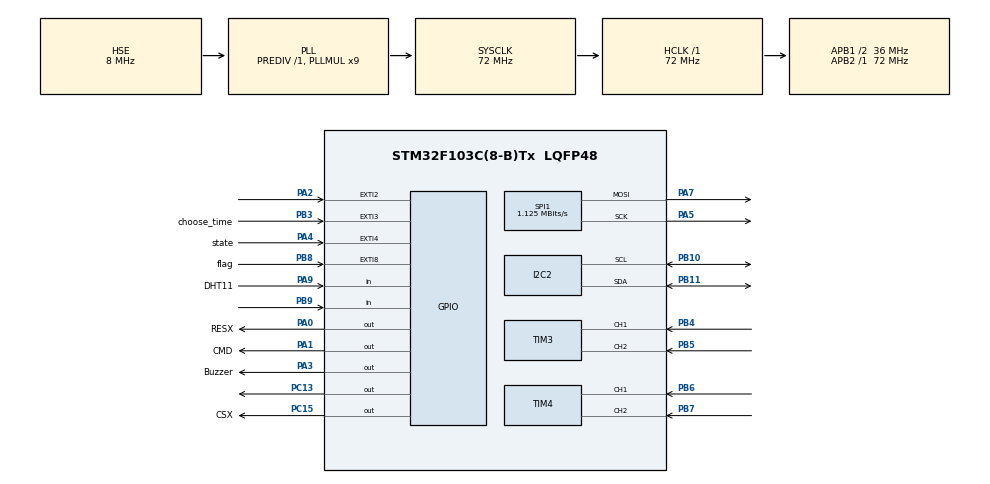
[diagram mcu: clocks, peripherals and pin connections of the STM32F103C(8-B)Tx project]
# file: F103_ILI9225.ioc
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Mcu.Family=STM32F1
Mcu.Name=STM32F103C(8-B)Tx
Mcu.Package=LQFP48
NVIC.EXTI2_IRQn=true\:0\:0\:true\:false\:true\:true\:true\:true
NVIC.EXTI3_IRQn=true\:0\:0\:true\:false\:true\:true\:true\:true
NVIC.EXTI4_IRQn=true\:0\:0\:true\:false\:true\:true\:true\:true
NVIC.EXTI9_5_IRQn=true\:0\:0\:true\:false\:true\:true\:true\:true
NVIC.PriorityGroup=NVIC_PRIORITYGROUP_4
NVIC.TIM3_IRQn=true\:1\:0\:true\:false\:true\:true\:true\:true
NVIC.TIM4_IRQn=true\:0\:0\:false\:false\:true\:true\:true\:true
PA0-WKUP.GPIO_Label=RESX
PA0-WKUP.Signal=GPIO_Output
PA1.GPIO_Label=CMD
PA1.Signal=GPIO_Output
PA13.Mode=Serial_Wire
PA13.Signal=SYS_JTMS-SWDIO
PA14.Mode=Serial_Wire
PA14.Signal=SYS_JTCK-SWCLK
PA2.GPIO_ModeDefaultEXTI=GPIO_MODE_IT_FALLING
PA2.GPIO_PuPd=GPIO_PULLUP
PA2.Signal=GPXTI2
PA3.GPIO_Label=Buzzer
PA3.Signal=GPIO_Output
PA4.GPIO_Label=state
PA4.GPIO_ModeDefaultEXTI=GPIO_MODE_IT_RISING_FALLING
PA4.GPIO_PuPd=GPIO_PULLUP
PA4.Signal=GPXTI4
PA5.Mode=TX_Only_Simplex_Unidirect_Master
PA5.Signal=SPI1_SCK
PA7.Mode=TX_Only_Simplex_Unidirect_Master
PA7.Signal=SPI1_MOSI
PA9.GPIO_Label=DHT11
PA9.Signal=GPIO_Input
PB10.Mode=I2C
PB10.Signal=I2C2_SCL
PB11.Mode=I2C
PB11.Signal=I2C2_SDA
PB3.GPIO_Label=choose_time
PB3.GPIO_ModeDefaultEXTI=GPIO_MODE_IT_FALLING
PB3.GPIO_PuPd=GPIO_PULLUP
PB3.Signal=GPXTI3
PB4.Signal=S_TIM3_CH1
PB5.Signal=S_TIM3_CH2
PB6.Signal=S_TIM4_CH1
PB7.Signal=S_TIM4_CH2
PB8.GPIO_Label=flag
PB8.GPIO_ModeDefaultEXTI=GPIO_MODE_IT_FALLING
PB8.GPIO_PuPd=GPIO_PULLUP
PB8.Signal=GPXTI8
PB9.Signal=GPIO_Input
PC13-TAMPER-RTC.Signal=GPIO_Output
PC15-OSC32_OUT.GPIO_Label=CSX
PC15-OSC32_OUT.Signal=GPIO_Output
PD0-OSC_IN.Mode=HSE-External-Oscillator
PD0-OSC_IN.Signal=RCC_OSC_IN
PD1-OSC_OUT.Mode=HSE-External-Oscillator
PD1-OSC_OUT.Signal=RCC_OSC_OUT
ProjectManager.HeapSize=0x200
ProjectManager.StackSize=0x400
ProjectManager.TargetToolchain=STM32CubeIDE
RCC.AHBFreq_Value=72000000
RCC.APB1CLKDivider=RCC_HCLK_DIV2
RCC.APB1Freq_Value=36000000
RCC.APB1TimFreq_Value=72000000
RCC.APB2Freq_Value=72000000
RCC.APB2TimFreq_Value=72000000
RCC.HCLKFreq_Value=72000000
RCC.PLLMUL=RCC_PLL_MUL9
RCC.PLLSourceVirtual=RCC_PLLSOURCE_HSE
RCC.SYSCLKFreq_VALUE=72000000
RCC.SYSCLKSource=RCC_SYSCLKSOURCE_PLLCLK
RCC.USBFreq_Value=72000000
SH.S_TIM3_CH1.0=TIM3_CH1,Encoder_Interface
SH.S_TIM3_CH2.0=TIM3_CH2,Encoder_Interface
SH.S_TIM4_CH1.0=TIM4_CH1,Encoder_Interface
SH.S_TIM4_CH2.0=TIM4_CH2,Encoder_Interface
SPI1.BaudRatePrescaler=SPI_BAUDRATEPRESCALER_64
SPI1.CalculateBaudRate=1.125 MBits/s
SPI1.Direction=SPI_DIRECTION_2LINES
SPI1.Mode=SPI_MODE_MASTER
SPI1.VirtualType=VM_MASTER
TIM2.Prescaler=72-1
TIM3.AutoReloadPreload=TIM_AUTORELOAD_PRELOAD_ENABLE
TIM3.EncoderMode=TIM_ENCODERMODE_TI12
TIM3.IC1Filter=10
TIM3.IC1Polarity=TIM_ICPOLARITY_RISING
TIM3.IC2Filter=10
TIM3.IC2Polarity=TIM_ICPOLARITY_RISING
TIM4.AutoReloadPreload=TIM_AUTORELOAD_PRELOAD_ENABLE
TIM4.EncoderMode=TIM_ENCODERMODE_TI12
TIM4.IC1Filter=10
TIM4.IC1Prescaler=TIM_ICPSC_DIV1
TIM4.IC2Filter=10
TIM4.IC2Prescaler=TIM_ICPSC_DIV1
VP_TIM2_VS_ClockSourceINT.Mode=Internal
board=custom

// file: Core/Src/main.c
/* USER CODE BEGIN Header */
/**
 ******************************************************************************
 * @file           : main.c
 * @brief          : Main program body
 ******************************************************************************
 * @attention
 *
 * Copyright (c) 2023 STMicroelectronics.
 * All rights reserved.
 *
 * This software is licensed under terms that can be found in the LICENSE file
 * in the root directory of this software component.
 * If no LICENSE file comes with this software, it is provided AS-IS.
 *
 ******************************************************************************
 */
/* USER CODE END Header */
#include "main.h"

/* USER CODE BEGIN Includes */
//#include "main.h"

/* USER CODE END Includes */

I2C_HandleTypeDef hi2c2;

SPI_HandleTypeDef hspi1;

TIM_HandleTypeDef htim2;
TIM_HandleTypeDef htim3;
TIM_HandleTypeDef htim4;

/* USER CODE BEGIN PV */
uint8_t c;
/* USER CODE END PV */

void SystemClock_Config(void);
static void MX_GPIO_Init(void);
static void MX_I2C2_Init(void);
static void MX_SPI1_Init(void);
static void MX_TIM3_Init(void);
static void MX_TIM2_Init(void);
static void MX_TIM4_Init(void);

int main(void)
{

  /* MCU Configuration--------------------------------------------------------*/

  /* Reset of all peripherals, Initializes the Flash interface and the Systick. */
  HAL_Init();

  /* Configure the system clock */
  SystemClock_Config();

  /* Initialize all configured peripherals */
  MX_GPIO_Init();
  MX_I2C2_Init();
  MX_SPI1_Init();
  MX_TIM3_Init();
  MX_TIM2_Init();
  MX_TIM4_Init();
  /* USER CODE BEGIN 2 */
  app_main();
  /* USER CODE END 2 */

  /* Infinite loop */
    while (1)
    {

    }
}

void SystemClock_Config(void)
{
  RCC_OscInitTypeDef RCC_OscInitStruct = {0};
  RCC_ClkInitTypeDef RCC_ClkInitStruct = {0};

  /** Initializes the RCC Oscillators according to the specified parameters
  * in the RCC_OscInitTypeDef structure.
  */
  RCC_OscInitStruct.OscillatorType = RCC_OSCILLATORTYPE_HSE;
  RCC_OscInitStruct.HSEState = RCC_HSE_ON;
  RCC_OscInitStruct.HSEPredivValue = RCC_HSE_PREDIV_DIV1;
  RCC_OscInitStruct.HSIState = RCC_HSI_ON;
  RCC_OscInitStruct.PLL.PLLState = RCC_PLL_ON;
  RCC_OscInitStruct.PLL.PLLSource = RCC_PLLSOURCE_HSE;
  RCC_OscInitStruct.PLL.PLLMUL = RCC_PLL_MUL9;
  if (HAL_RCC_OscConfig(&RCC_OscInitStruct) != HAL_OK)
  {
    Error_Handler();
  }

  /** Initializes the CPU, AHB and APB buses clocks
  */
  RCC_ClkInitStruct.ClockType = RCC_CLOCKTYPE_HCLK|RCC_CLOCKTYPE_SYSCLK
                              |RCC_CLOCKTYPE_PCLK1|RCC_CLOCKTYPE_PCLK2;
  RCC_ClkInitStruct.SYSCLKSource = RCC_SYSCLKSOURCE_PLLCLK;
  RCC_ClkInitStruct.AHBCLKDivider = RCC_SYSCLK_DIV1;
  RCC_ClkInitStruct.APB1CLKDivider = RCC_HCLK_DIV2;
  RCC_ClkInitStruct.APB2CLKDivider = RCC_HCLK_DIV1;

  if (HAL_RCC_ClockConfig(&RCC_ClkInitStruct, FLASH_LATENCY_2) != HAL_OK)
  {
    Error_Handler();
  }
}

static void MX_I2C2_Init(void)
{

  hi2c2.Instance = I2C2;
  hi2c2.Init.ClockSpeed = 100000;
  hi2c2.Init.DutyCycle = I2C_DUTYCYCLE_2;
  hi2c2.Init.OwnAddress1 = 0;
  hi2c2.Init.AddressingMode = I2C_ADDRESSINGMODE_7BIT;
  hi2c2.Init.DualAddressMode = I2C_DUALADDRESS_DISABLE;
  hi2c2.Init.OwnAddress2 = 0;
  hi2c2.Init.GeneralCallMode = I2C_GENERALCALL_DISABLE;
  hi2c2.Init.NoStretchMode = I2C_NOSTRETCH_DISABLE;
  if (HAL_I2C_Init(&hi2c2) != HAL_OK)
  {
    Error_Handler();
  }

}

static void MX_SPI1_Init(void)
{

  /* SPI1 parameter configuration*/
  hspi1.Instance = SPI1;
  hspi1.Init.Mode = SPI_MODE_MASTER;
  hspi1.Init.Direction = SPI_DIRECTION_2LINES;
  hspi1.Init.DataSize = SPI_DATASIZE_8BIT;
  hspi1.Init.CLKPolarity = SPI_POLARITY_LOW;
  hspi1.Init.CLKPhase = SPI_PHASE_1EDGE;
  hspi1.Init.NSS = SPI_NSS_SOFT;
  hspi1.Init.BaudRatePrescaler = SPI_BAUDRATEPRESCALER_64;
  hspi1.Init.FirstBit = SPI_FIRSTBIT_MSB;
  hspi1.Init.TIMode = SPI_TIMODE_DISABLE;
  hspi1.Init.CRCCalculation = SPI_CRCCALCULATION_DISABLE;
  hspi1.Init.CRCPolynomial = 10;
  if (HAL_SPI_Init(&hspi1) != HAL_OK)
  {
    Error_Handler();
  }

}

static void MX_TIM2_Init(void)
{

  TIM_ClockConfigTypeDef sClockSourceConfig = {0};
  TIM_MasterConfigTypeDef sMasterConfig = {0};

  htim2.Instance = TIM2;
  htim2.Init.Prescaler = 72-1;
  htim2.Init.CounterMode = TIM_COUNTERMODE_UP;
  htim2.Init.Period = 65535;
  htim2.Init.ClockDivision = TIM_CLOCKDIVISION_DIV1;
  htim2.Init.AutoReloadPreload = TIM_AUTORELOAD_PRELOAD_DISABLE;
  if (HAL_TIM_Base_Init(&htim2) != HAL_OK)
  {
    Error_Handler();
  }
  sClockSourceConfig.ClockSource = TIM_CLOCKSOURCE_INTERNAL;
  if (HAL_TIM_ConfigClockSource(&htim2, &sClockSourceConfig) != HAL_OK)
  {
    Error_Handler();
  }
  sMasterConfig.MasterOutputTrigger = TIM_TRGO_RESET;
  sMasterConfig.MasterSlaveMode = TIM_MASTERSLAVEMODE_DISABLE;
  if (HAL_TIMEx_MasterConfigSynchronization(&htim2, &sMasterConfig) != HAL_OK)
  {
    Error_Handler();
  }

}

static void MX_TIM3_Init(void)
{

  TIM_Encoder_InitTypeDef sConfig = {0};
  TIM_MasterConfigTypeDef sMasterConfig = {0};

  htim3.Instance = TIM3;
  htim3.Init.Prescaler = 0;
  htim3.Init.CounterMode = TIM_COUNTERMODE_UP;
  htim3.Init.Period = 65535;
  htim3.Init.ClockDivision = TIM_CLOCKDIVISION_DIV1;
  htim3.Init.AutoReloadPreload = TIM_AUTORELOAD_PRELOAD_ENABLE;
  sConfig.EncoderMode = TIM_ENCODERMODE_TI12;
  sConfig.IC1Polarity = TIM_ICPOLARITY_RISING;
  sConfig.IC1Selection = TIM_ICSELECTION_DIRECTTI;
  sConfig.IC1Prescaler = TIM_ICPSC_DIV1;
  sConfig.IC1Filter = 10;
  sConfig.IC2Polarity = TIM_ICPOLARITY_RISING;
  sConfig.IC2Selection = TIM_ICSELECTION_DIRECTTI;
  sConfig.IC2Prescaler = TIM_ICPSC_DIV1;
  sConfig.IC2Filter = 10;
  if (HAL_TIM_Encoder_Init(&htim3, &sConfig) != HAL_OK)
  {
    Error_Handler();
  }
  sMasterConfig.MasterOutputTrigger = TIM_TRGO_RESET;
  sMasterConfig.MasterSlaveMode = TIM_MASTERSLAVEMODE_DISABLE;
  if (HAL_TIMEx_MasterConfigSynchronization(&htim3, &sMasterConfig) != HAL_OK)
  {
    Error_Handler();
  }

}

static void MX_TIM4_Init(void)
{

  TIM_Encoder_InitTypeDef sConfig = {0};
  TIM_MasterConfigTypeDef sMasterConfig = {0};

  htim4.Instance = TIM4;
  htim4.Init.Prescaler = 0;
  htim4.Init.CounterMode = TIM_COUNTERMODE_UP;
  htim4.Init.Period = 65535;
  htim4.Init.ClockDivision = TIM_CLOCKDIVISION_DIV1;
  htim4.Init.AutoReloadPreload = TIM_AUTORELOAD_PRELOAD_ENABLE;
  sConfig.EncoderMode = TIM_ENCODERMODE_TI12;
  sConfig.IC1Polarity = TIM_ICPOLARITY_RISING;
  sConfig.IC1Selection = TIM_ICSELECTION_DIRECTTI;
  sConfig.IC1Prescaler = TIM_ICPSC_DIV1;
  sConfig.IC1Filter = 10;
  sConfig.IC2Polarity = TIM_ICPOLARITY_RISING;
  sConfig.IC2Selection = TIM_ICSELECTION_DIRECTTI;
  sConfig.IC2Prescaler = TIM_ICPSC_DIV1;
  sConfig.IC2Filter = 10;
  if (HAL_TIM_Encoder_Init(&htim4, &sConfig) != HAL_OK)
  {
    Error_Handler();
  }
  sMasterConfig.MasterOutputTrigger = TIM_TRGO_RESET;
  sMasterConfig.MasterSlaveMode = TIM_MASTERSLAVEMODE_DISABLE;
  if (HAL_TIMEx_MasterConfigSynchronization(&htim4, &sMasterConfig) != HAL_OK)
  {
    Error_Handler();
  }

}

static void MX_GPIO_Init(void)
{
  GPIO_InitTypeDef GPIO_InitStruct = {0};

  /* GPIO Ports Clock Enable */
  __HAL_RCC_GPIOC_CLK_ENABLE();
  __HAL_RCC_GPIOD_CLK_ENABLE();
  __HAL_RCC_GPIOA_CLK_ENABLE();
  __HAL_RCC_GPIOB_CLK_ENABLE();

  /*Configure GPIO pin Output Level */
  HAL_GPIO_WritePin(GPIOC, GPIO_PIN_13|CSX_Pin, GPIO_PIN_RESET);

  /*Configure GPIO pin Output Level */
  HAL_GPIO_WritePin(GPIOA, RESX_Pin|CMD_Pin|Buzzer_Pin, GPIO_PIN_RESET);

  /*Configure GPIO pins : PC13 CSX_Pin */
  GPIO_InitStruct.Pin = GPIO_PIN_13|CSX_Pin;
  GPIO_InitStruct.Mode = GPIO_MODE_OUTPUT_PP;
  GPIO_InitStruct.Pull = GPIO_NOPULL;
  GPIO_InitStruct.Speed = GPIO_SPEED_FREQ_LOW;
  HAL_GPIO_Init(GPIOC, &GPIO_InitStruct);

  /*Configure GPIO pins : RESX_Pin CMD_Pin Buzzer_Pin */
  GPIO_InitStruct.Pin = RESX_Pin|CMD_Pin|Buzzer_Pin;
  GPIO_InitStruct.Mode = GPIO_MODE_OUTPUT_PP;
  GPIO_InitStruct.Pull = GPIO_NOPULL;
  GPIO_InitStruct.Speed = GPIO_SPEED_FREQ_LOW;
  HAL_GPIO_Init(GPIOA, &GPIO_InitStruct);

  /*Configure GPIO pin : PA2 */
  GPIO_InitStruct.Pin = GPIO_PIN_2;
  GPIO_InitStruct.Mode = GPIO_MODE_IT_FALLING;
  GPIO_InitStruct.Pull = GPIO_PULLUP;
  HAL_GPIO_Init(GPIOA, &GPIO_InitStruct);

  /*Configure GPIO pin : state_Pin */
  GPIO_InitStruct.Pin = state_Pin;
  GPIO_InitStruct.Mode = GPIO_MODE_IT_RISING_FALLING;
  GPIO_InitStruct.Pull = GPIO_PULLUP;
  HAL_GPIO_Init(state_GPIO_Port, &GPIO_InitStruct);

  /*Configure GPIO pin : DHT11_Pin */
  GPIO_InitStruct.Pin = DHT11_Pin;
  GPIO_InitStruct.Mode = GPIO_MODE_INPUT;
  GPIO_InitStruct.Pull = GPIO_NOPULL;
  HAL_GPIO_Init(DHT11_GPIO_Port, &GPIO_InitStruct);

  /*Configure GPIO pins : choose_time_Pin flag_Pin */
  GPIO_InitStruct.Pin = choose_time_Pin|flag_Pin;
  GPIO_InitStruct.Mode = GPIO_MODE_IT_FALLING;
  GPIO_InitStruct.Pull = GPIO_PULLUP;
  HAL_GPIO_Init(GPIOB, &GPIO_InitStruct);

  /*Configure GPIO pin : PB9 */
  GPIO_InitStruct.Pin = GPIO_PIN_9;
  GPIO_InitStruct.Mode = GPIO_MODE_INPUT;
  GPIO_InitStruct.Pull = GPIO_NOPULL;
  HAL_GPIO_Init(GPIOB, &GPIO_InitStruct);

  /* EXTI interrupt init*/
  HAL_NVIC_SetPriority(EXTI2_IRQn, 0, 0);
  HAL_NVIC_EnableIRQ(EXTI2_IRQn);

  HAL_NVIC_SetPriority(EXTI3_IRQn, 0, 0);
  HAL_NVIC_EnableIRQ(EXTI3_IRQn);

  HAL_NVIC_SetPriority(EXTI4_IRQn, 0, 0);
  HAL_NVIC_EnableIRQ(EXTI4_IRQn);

  HAL_NVIC_SetPriority(EXTI9_5_IRQn, 0, 0);
  HAL_NVIC_EnableIRQ(EXTI9_5_IRQn);

}

void Error_Handler(void)
{
    __disable_irq();
    while (1)
    {
    }
}
